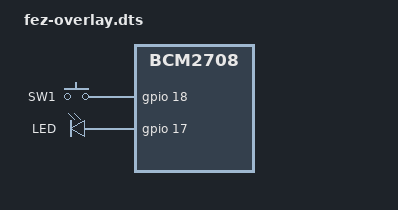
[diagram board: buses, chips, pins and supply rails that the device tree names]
// Enable the Hat interface
/dts-v1/;
/plugin/;

/ {
	compatible = "brcm,bcm2708";

    fragment@0 {
		target-path = "/";
		__overlay__ {
      buttons_pins {
        compatible = "gpio-keys";
        sw01 {
          label = "SW1";
          linux,code = <2>;
          gpios = <&gpio 18 0>;
        };
      };
		};
	};

	fragment@1 {
		target-path = "/";
		__overlay__ {
			leds_pins {
				compatible = "gpio-leds";

				led {
					label = "LED";
					gpios = <&gpio 17 0>;
					linux,default-trigger = "timer";
				};
			};
		};
	};

	fragment@2 {
		target = <&gpio>;
		__overlay__ {

			buttons_pins: buttons_pins{
				brcm,pins = <18>;
				brcm,function = <0>;
			};

			leds_pins: leds_pins {
				brcm,pins = <17>;
				brcm,function = <1>;
			};
		};
	};
};
